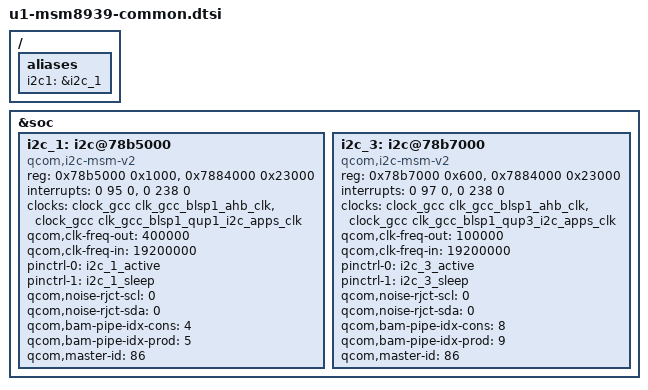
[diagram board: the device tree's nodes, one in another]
/* Copyright (c) 2014-2015, The Linux Foundation. All rights reserved.
 *
 * This program is free software; you can redistribute it and/or modify
 * it under the terms of the GNU General Public License version 2 and
 * only version 2 as published by the Free Software Foundation.
 *
 * This program is distributed in the hope that it will be useful,
 * but WITHOUT ANY WARRANTY; without even the implied warranty of
 * MERCHANTABILITY or FITNESS FOR A PARTICULAR PURPOSE.  See the
 * GNU General Public License for more details.
 */

/ {
	aliases {
		i2c1 = &i2c_1;
	};
};

&soc {
	i2c_1: i2c@78b5000 { /* BLSP1 QUP1 */
		compatible = "qcom,i2c-msm-v2";
	#address-cells=<1>;
	#size-cells=<0>;
		reg-names = "qup_phys_addr", "bam_phys_addr";
		reg = <0x78b5000 0x1000>,
				<0x7884000 0x23000>;
		interrupt-names = "qup_irq", "bam_irq";
		interrupts = <0 95 0>, <0 238 0>;
		clocks = <&clock_gcc clk_gcc_blsp1_ahb_clk>,
				<&clock_gcc clk_gcc_blsp1_qup1_i2c_apps_clk>;
		clock-names = "iface_clk", "core_clk";
		qcom,clk-freq-out = <400000>;
		qcom,clk-freq-in  = <19200000>;
		pinctrl-names = "i2c_active", "i2c_sleep";
		pinctrl-0 = <&i2c_1_active>;
		pinctrl-1 = <&i2c_1_sleep>;
		qcom,noise-rjct-scl = <0>;
		qcom,noise-rjct-sda = <0>;
		qcom,bam-pipe-idx-cons = <4>;
		qcom,bam-pipe-idx-prod = <5>;
		qcom,master-id = <86>;
	};

	i2c_3: i2c@78b7000 { /* BLSP1 QUP3 */
		compatible = "qcom,i2c-msm-v2";
		#address-cells = <1>;
		#size-cells = <0>;
		reg-names = "qup_phys_addr", "bam_phys_addr";
		reg = <0x78b7000 0x600>,
		      <0x7884000 0x23000>;
		interrupt-names = "qup_irq", "bam_irq";
		interrupts = <0 97 0>, <0 238 0>;
		clocks = <&clock_gcc clk_gcc_blsp1_ahb_clk>,
			 <&clock_gcc clk_gcc_blsp1_qup3_i2c_apps_clk>;
		clock-names = "iface_clk", "core_clk";
		qcom,clk-freq-out = <100000>;
		qcom,clk-freq-in  = <19200000>;
		pinctrl-names = "i2c_active", "i2c_sleep";
		pinctrl-0 = <&i2c_3_active>;
		pinctrl-1 = <&i2c_3_sleep>;
		qcom,noise-rjct-scl = <0>;
		qcom,noise-rjct-sda = <0>;
		qcom,bam-pipe-idx-cons = <8>;
		qcom,bam-pipe-idx-prod = <9>;
		qcom,master-id = <86>;
	};
};
